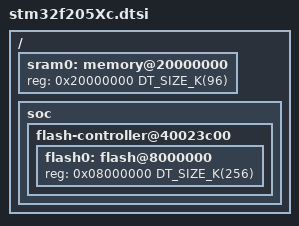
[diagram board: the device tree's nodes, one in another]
/*
 * Copyright (c) 2023 TiaC Systems
 *
 * SPDX-License-Identifier: Apache-2.0
 */

#include <mem.h>
#include <st/f2/stm32f2.dtsi>

/ {
	sram0: memory@20000000 {
		reg = <0x20000000 DT_SIZE_K(96)>;
	};

	soc {
		flash-controller@40023c00 {
			flash0: flash@8000000 {
				reg = <0x08000000 DT_SIZE_K(256)>;
			};
		};
	};
};
